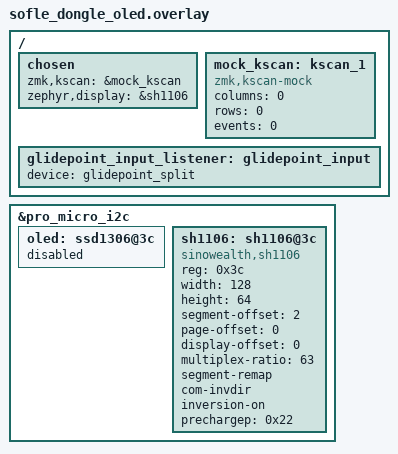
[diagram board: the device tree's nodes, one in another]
#include "sofle.dtsi"
#include "sofle_cirque.dtsi"

/ {
    chosen {
        zmk,kscan = &mock_kscan;
        zephyr,display = &sh1106;
    };

    mock_kscan: kscan_1 {
        compatible = "zmk,kscan-mock";
        columns = <0>;
        rows = <0>;
        events = <0>;
    };
};

/delete-node/ &kscan0;

// Disable ssd1306 display and use sh1106 display for dongle.
&pro_micro_i2c {
    status = "okay";

    oled: ssd1306@3c {
        status = "disabled";
    };
    
    // Display Dongle OLED
    sh1106: sh1106@3c {
        status = "okay";
        compatible = "sinowealth,sh1106";
        reg = <0x3c>;
        width = <128>;
        height = <64>;
        segment-offset = <2>;
        page-offset = <0>;
        display-offset = <0>;
        multiplex-ratio = <63>;
        segment-remap;
        com-invdir;
        inversion-on;
        prechargep = <0x22>;
    };
};

// Cirque Trackpad
// Split peripheral input relay module central. (zmk-split-peripheral-input-relay)
// / {
// 	glidepoint1: virtual_input {
// 		compatible = "zmk,virtual-input";
// 	};

// 	input_relay_config_102 {
// 		compatible = "zmk,split-peripheral-input-relay";
// 		relay-channel = <102>;
// 		device = <&glidepoint1>;
// 	};
// };

// ZMK Input Split (PR#2477)
/ {
    glidepoint_input_listener: glidepoint_input {
        //compatible = "zmk,input-listener";    // Don't need this if there's one in .keymap
        device = <&glidepoint_split>;
        // input-processors = <&zip_xy_transform (INPUT_TRANSFORM_Y_INVERT)>,
        //                    <&zip_scroll_transform (INPUT_TRANSFORM_Y_INVERT)>;
    };
};
